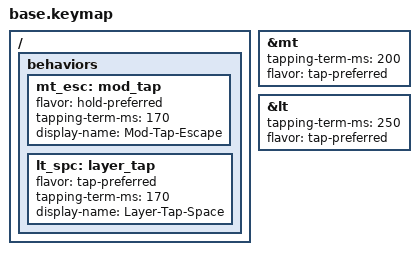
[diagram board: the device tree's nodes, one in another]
#include <behaviors.dtsi>
#include <dt-bindings/zmk/keys.h>
#include <dt-bindings/zmk/behaviors.h>

&mt {
  tapping-term-ms = <200>;
  flavor = "tap-preferred";
};

&lt {
  tapping-term-ms = <250>;
  flavor = "tap-preferred";
};

/ {
  behaviors {
    mt_esc: mod_tap {
            flavor = "hold-preferred";
            tapping-term-ms = <170>;
            display-name = "Mod-Tap-Escape";
    };

    lt_spc: layer_tap {
            flavor = "tap-preferred";
            tapping-term-ms = <170>;
            display-name = "Layer-Tap-Space";
    };
  };
};

// layers
#define _COLEMAK     0
#define _COLEMAK_MEH 1
#define _SYMBOL      2
#define _NUMPAD      3
#define _NAVIGATION  4
#define _FUNCTION    5
#define _ADJUST      6

// nice to have
#define XXXXXXX  &none
#define _______  &trans

// colemak layers
#define SYM      &mo _SYMBOL
#define NUM      &mo _NUMPAD
#define NAV      &mo _NAVIGATION
#define FUNC     &mo _FUNCTION
#define LHYPER   &kp LGUI
#define RHYPER   &kp RGUI

// additional layers
#define ADJUST   &mo _ADJUST

// layer mod taps
#define MT_SPACE &lt_spc _SYMBOL SPACE
#define MT_ESC   &mt_esc RSHFT  ESC

// home row mods
#define MT_A     &lt _COLEMAK_MEH A
#define MT_R     &mt LGUI  R
#define MT_S     &mt LALT  S
#define MT_T     &mt LCTRL T
#define MT_N     &mt RCTRL N
#define MT_E     &mt RALT  E
#define MT_I     &mt RGUI  I
#define MT_O     &lt _COLEMAK_MEH O

#define MT_DLLR  &mt LGUI  DLLR
#define MT_PRCNT &mt LALT  PRCNT
#define MT_CARET &mt LCTRL CARET
#define MT_EQUAL &mt RCTRL EQUAL
#define MT_LBKT  &mt RALT  LBKT
#define MT_RBKT  &mt RGUI  RBKT
 
// meh layer keys
#define LM_A     &kp LC(LS(LA(A)))
#define LM_B     &kp LC(LS(LA(B)))
#define LM_C     &kp LC(LS(LA(C)))
#define LM_D     &kp LC(LS(LA(D)))
#define LM_E     &kp LC(LS(LA(E)))
#define LM_F     &kp LC(LS(LA(F)))
#define LM_G     &kp LC(LS(LA(G)))
#define LM_H     &kp LC(LS(LA(H)))
#define LM_I     &kp LC(LS(LA(I)))
#define LM_J     &kp LC(LS(LA(J)))
#define LM_K     &kp LC(LS(LA(K)))
#define LM_L     &kp LC(LS(LA(L)))
#define LM_M     &kp LC(LS(LA(M)))
#define LM_N     &kp LC(LS(LA(N)))
#define LM_O     &kp LC(LS(LA(O)))
#define LM_P     &kp LC(LS(LA(P)))
#define LM_Q     &kp LC(LS(LA(Q)))
#define LM_R     &kp LC(LS(LA(R)))
#define LM_S     &kp LC(LS(LA(S)))
#define LM_T     &kp LC(LS(LA(T)))
#define LM_U     &kp LC(LS(LA(U)))
#define LM_V     &kp LC(LS(LA(V)))
#define LM_W     &kp LC(LS(LA(W)))
#define LM_X     &kp LC(LS(LA(X)))
#define LM_Y     &kp LC(LS(LA(Y)))
#define LM_Z     &kp LC(LS(LA(Z)))
#define LM_N1    &kp LC(LS(LA(N1)))
#define LM_N2    &kp LC(LS(LA(N2)))
#define LM_N3    &kp LC(LS(LA(N3)))
#define LM_N4    &kp LC(LS(LA(N4)))
#define LM_N5    &kp LC(LS(LA(N5)))
#define LM_N6    &kp LC(LS(LA(N6)))
#define LM_N7    &kp LC(LS(LA(N7)))
#define LM_N8    &kp LC(LS(LA(N8)))
#define LM_N9    &kp LC(LS(LA(N9)))
#define LM_N0    &kp LC(LS(LA(N0)))
#define LM_MINUS &kp LC(LS(LA(MINUS)))
#define LM_EQUAL &kp LC(LS(LA(EQUAL)))
#define LM_LBKT  &kp LC(LS(LA(LBKT)))
#define LM_RBKT  &kp LC(LS(LA(RBKT)))
#define LM_BSLH  &kp LC(LS(LA(BSLH)))
#define LM_SEMI  &kp LC(LS(LA(SEMI)))
#define LM_SQT   &kp LC(LS(LA(SQT)))
#define LM_GRAVE &kp LC(LS(LA(GRAVE)))
#define LM_COMMA &kp LC(LS(LA(COMMA)))
#define LM_DOT   &kp LC(LS(LA(DOT)))
#define LM_SLASH &kp LC(LS(LA(SLASH)))
#define LM_ESC   &kp LC(LS(LA(ESC)))
#define LM_TAB   &kp LC(LS(LA(TAB)))
#define LM_BSPC  &kp LC(LS(LA(BSPC)))
#define LM_ENTER &kp LC(LS(LA(ENTER)))
#define LM_SPACE &kp LC(LS(LA(SPACE)))
#define LM_UP    &kp LC(LS(LA(UP)))
#define LM_LEFT  &kp LC(LS(LA(LEFT)))
#define LM_DOWN  &kp LC(LS(LA(DOWN)))
#define LM_RIGHT &kp LC(LS(LA(RIGHT)))
#define LM_DEL   &kp LC(LS(LA(DEL)))
